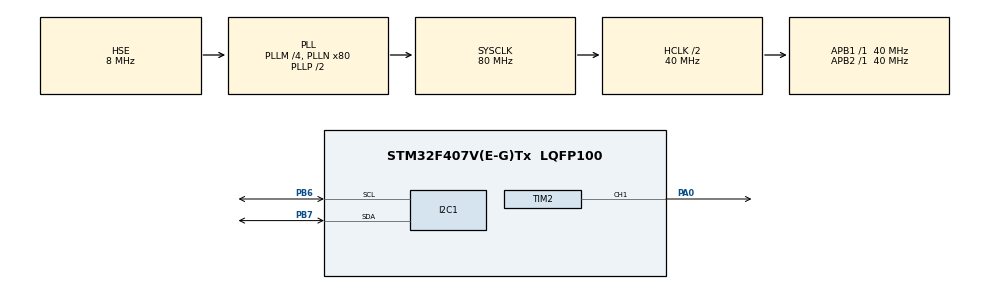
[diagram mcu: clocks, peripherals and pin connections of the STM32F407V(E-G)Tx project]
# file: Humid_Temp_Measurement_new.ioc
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Dma.Request0=TIM2_CH1
Dma.TIM2_CH1.0.Direction=DMA_MEMORY_TO_PERIPH
Dma.TIM2_CH1.0.FIFOMode=DMA_FIFOMODE_DISABLE
Dma.TIM2_CH1.0.Instance=DMA1_Stream5
Dma.TIM2_CH1.0.MemDataAlignment=DMA_MDATAALIGN_HALFWORD
Dma.TIM2_CH1.0.MemInc=DMA_MINC_ENABLE
Dma.TIM2_CH1.0.Mode=DMA_NORMAL
Dma.TIM2_CH1.0.PeriphDataAlignment=DMA_PDATAALIGN_HALFWORD
Dma.TIM2_CH1.0.PeriphInc=DMA_PINC_DISABLE
Dma.TIM2_CH1.0.Priority=DMA_PRIORITY_LOW
Mcu.Family=STM32F4
Mcu.Name=STM32F407V(E-G)Tx
Mcu.Package=LQFP100
NVIC.DMA1_Stream5_IRQn=true\:0\:0\:false\:false\:true\:false\:true\:true
NVIC.PriorityGroup=NVIC_PRIORITYGROUP_4
NVIC.TIM3_IRQn=true\:0\:0\:false\:false\:true\:true\:true\:true
PA0-WKUP.Signal=S_TIM2_CH1_ETR
PA13.Mode=Serial_Wire
PA13.Signal=SYS_JTMS-SWDIO
PA14.Mode=Serial_Wire
PA14.Signal=SYS_JTCK-SWCLK
PB6.Mode=I2C
PB6.Signal=I2C1_SCL
PB7.Mode=I2C
PB7.Signal=I2C1_SDA
PH0-OSC_IN.Mode=HSE-External-Oscillator
PH0-OSC_IN.Signal=RCC_OSC_IN
PH1-OSC_OUT.Mode=HSE-External-Oscillator
PH1-OSC_OUT.Signal=RCC_OSC_OUT
ProjectManager.HeapSize=0x200
ProjectManager.StackSize=0x400
ProjectManager.TargetToolchain=STM32CubeIDE
RCC.48MHZClocksFreq_Value=40000000
RCC.AHBCLKDivider=RCC_SYSCLK_DIV2
RCC.AHBFreq_Value=40000000
RCC.APB1Freq_Value=40000000
RCC.APB1TimFreq_Value=40000000
RCC.APB2Freq_Value=40000000
RCC.APB2TimFreq_Value=40000000
RCC.CortexFreq_Value=40000000
RCC.HCLKFreq_Value=40000000
RCC.HSE_VALUE=8000000
RCC.HSI_VALUE=16000000
RCC.LSE_VALUE=32768
RCC.PLLM=4
RCC.PLLN=80
RCC.PLLSourceVirtual=RCC_PLLSOURCE_HSE
RCC.SYSCLKFreq_VALUE=80000000
RCC.SYSCLKSource=RCC_SYSCLKSOURCE_PLLCLK
RCC.VCOOutputFreq_Value=160000000
SH.S_TIM2_CH1_ETR.0=TIM2_CH1,PWM Generation1 CH1
TIM2.Channel-PWM\ Generation1\ CH1=TIM_CHANNEL_1
TIM2.Period=2000
TIM2.Prescaler=40-1
TIM3.Period=0xffff-1
TIM3.Prescaler=40-1
VP_TIM2_VS_ClockSourceINT.Mode=Internal
VP_TIM3_VS_ClockSourceINT.Mode=Internal
board=custom

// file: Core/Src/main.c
/* USER CODE BEGIN Header */
/**
  ******************************************************************************
  * @file           : main.c
  * @brief          : Main program body
  ******************************************************************************
  * @attention
  *
  * Copyright (c) 2024 STMicroelectronics.
  * All rights reserved.
  *
  * This software is licensed under terms that can be found in the LICENSE file
  * in the root directory of this software component.
  * If no LICENSE file comes with this software, it is provided AS-IS.
  *
  ******************************************************************************
  */
/* USER CODE END Header */
#include "main.h"

/* USER CODE BEGIN Includes */
#include "i2c-lcd.h"
#include "stdio.h"
#include "DHT11.h"
/* USER CODE END Includes */

I2C_HandleTypeDef hi2c1;

TIM_HandleTypeDef htim2;
TIM_HandleTypeDef htim3;
DMA_HandleTypeDef hdma_tim2_ch1;

void SystemClock_Config(void);
static void MX_GPIO_Init(void);
static void MX_DMA_Init(void);
static void MX_I2C1_Init(void);
static void MX_TIM2_Init(void);
static void MX_TIM3_Init(void);

/* USER CODE BEGIN PFP */
/********************************DHT11**********************************/
void display_Temp(float Temp);
void display_Humid(float RH);

/********************************DS3231**********************************/
#define DS3231_ADDRESS 0xD0

uint8_t dec_To_Bcd(int val);
int bcd_To_Dec(uint8_t val);

void set_Time(uint8_t sec, uint8_t min, uint8_t hour, uint8_t dow, uint8_t dom,
			  uint8_t month, uint8_t year);
void get_Time(void);

typedef struct {
	uint8_t second;
	uint8_t minute;
	uint8_t hour;
	uint8_t dayOfWeek;
	uint8_t dayOfMonth;
	uint8_t month;
	uint8_t year;
} TIME;
/* USER CODE END PFP */

/* USER CODE BEGIN 0 */
/********************************DHT11**********************************/
uint8_t RHI, RHD, TCI, TCD, SUM;
float tCelsius = 0;
float tFahrenheit = 0;
float RH = 0;

void display_Temp(float Temp) {
	char str[10];
	lcd_put_cur(0, 0);
	sprintf(str, "T:%.1f*C", Temp);
	lcd_send_string(str);
}

void display_Humid(float RH) {
	char str[10];
	lcd_put_cur(0, 9);
	sprintf(str, "H:%.1f", RH);
	lcd_send_string(str);
}

/********************************DS3231**********************************/
TIME time;

uint8_t dec_To_Bcd(int val) {
	return (uint8_t)((val/10*16) + (val%10));
}

int bcd_To_Dec(uint8_t val) {
	return (int)((val/16*10) + (val%16));
}

void set_Time(uint8_t sec, uint8_t min, uint8_t hour, uint8_t dow, uint8_t dom,
			  uint8_t month, uint8_t year) {
	uint8_t set_time_buffer[7];
	set_time_buffer[0] = dec_To_Bcd(sec);
	set_time_buffer[1] = dec_To_Bcd(min);
	set_time_buffer[2] = dec_To_Bcd(hour);
	set_time_buffer[3] = dec_To_Bcd(dow);
	set_time_buffer[4] = dec_To_Bcd(dom);
	set_time_buffer[5] = dec_To_Bcd(month);
	set_time_buffer[6] = dec_To_Bcd(year);

	HAL_I2C_Mem_Write(&hi2c1, DS3231_ADDRESS, 0x00, 1, set_time_buffer, 7, 1000);
}

void get_Time(void) {
	uint8_t get_time_buffer[7];
	HAL_I2C_Mem_Read(&hi2c1, DS3231_ADDRESS, 0x00, 1, get_time_buffer, 7, 1000);

	time.second 	= bcd_To_Dec(get_time_buffer[0]);
	time.minute 	= bcd_To_Dec(get_time_buffer[1]);
	time.hour 		= bcd_To_Dec(get_time_buffer[2]);
	time.dayOfWeek 	= bcd_To_Dec(get_time_buffer[3]);
	time.dayOfMonth = bcd_To_Dec(get_time_buffer[4]);
	time.month 		= bcd_To_Dec(get_time_buffer[5]);
	time.year 		= bcd_To_Dec(get_time_buffer[6]);
}

/* USER CODE END 0 */

int main(void)
{

  /* MCU Configuration--------------------------------------------------------*/

  /* Reset of all peripherals, Initializes the Flash interface and the Systick. */
  HAL_Init();

  /* Configure the system clock */
  SystemClock_Config();

  /* Initialize all configured peripherals */
  MX_GPIO_Init();
  MX_DMA_Init();
  MX_I2C1_Init();
  MX_TIM2_Init();
  MX_TIM3_Init();
  /* USER CODE BEGIN 2 */
  HAL_TIM_Base_Start(&htim3);
  HAL_TIM_Base_Start_IT(&htim3);

  HAL_TIM_PWM_Start(&htim2, TIM_CHANNEL_1);
  /* USER CODE END 2 */

  /* Infinite loop */
  /* USER CODE BEGIN WHILE */

  lcd_init();
  lcd_put_cur(0, 0);

  lcd_send_string("Hello world!");

  HAL_Delay(4000);
  lcd_clear();

//  set_Time(30, 12, 21, 6, 12, 4, 24);
  char time_buffer[30];

  while (1)
  {
	  display_Temp(tCelsius);
	  display_Humid(RH);

	  if(DHT11_Start()) {
		  RHI = DHT11_Read(); // Relative humidity integral
		  RHD = DHT11_Read(); // Relative humidity decimal
		  TCI = DHT11_Read(); // Celsius integral
		  TCD = DHT11_Read(); // Celsius decimal
		  SUM = DHT11_Read(); // Check sum

		  if(SUM == RHI + RHD + TCI + TCD) {
			  // Can use RHI and TCI for any purposes if whole number only needed
			  tCelsius = (float)TCI + (float)(TCD/10.0);
			  tFahrenheit = tCelsius * 9/5 + 32;
			  RH = (float)RHI + (float)(RHD/10.0);
			  // Can use tCelsius, tFahrenheit and RH for any purposes
		  }
	  }

	  get_Time();
	  sprintf(time_buffer, "%02d:%02d", time.hour, time.minute);
	  lcd_put_cur(1, 0);
	  lcd_send_string(time_buffer);

	  sprintf(time_buffer, "%02d-%02d-20%02d", time.dayOfMonth, time.month, time.year);
	  lcd_put_cur(1, 6);
	  lcd_send_string(time_buffer);

	  HAL_Delay(1000);
    /* USER CODE END WHILE */

  }
}

void SystemClock_Config(void)
{
  RCC_OscInitTypeDef RCC_OscInitStruct = {0};
  RCC_ClkInitTypeDef RCC_ClkInitStruct = {0};

  /** Configure the main internal regulator output voltage
  */
  __HAL_RCC_PWR_CLK_ENABLE();
  __HAL_PWR_VOLTAGESCALING_CONFIG(PWR_REGULATOR_VOLTAGE_SCALE1);

  /** Initializes the RCC Oscillators according to the specified parameters
  * in the RCC_OscInitTypeDef structure.
  */
  RCC_OscInitStruct.OscillatorType = RCC_OSCILLATORTYPE_HSE;
  RCC_OscInitStruct.HSEState = RCC_HSE_ON;
  RCC_OscInitStruct.PLL.PLLState = RCC_PLL_ON;
  RCC_OscInitStruct.PLL.PLLSource = RCC_PLLSOURCE_HSE;
  RCC_OscInitStruct.PLL.PLLM = 4;
  RCC_OscInitStruct.PLL.PLLN = 80;
  RCC_OscInitStruct.PLL.PLLP = RCC_PLLP_DIV2;
  RCC_OscInitStruct.PLL.PLLQ = 4;
  if (HAL_RCC_OscConfig(&RCC_OscInitStruct) != HAL_OK)
  {
    Error_Handler();
  }

  /** Initializes the CPU, AHB and APB buses clocks
  */
  RCC_ClkInitStruct.ClockType = RCC_CLOCKTYPE_HCLK|RCC_CLOCKTYPE_SYSCLK
                              |RCC_CLOCKTYPE_PCLK1|RCC_CLOCKTYPE_PCLK2;
  RCC_ClkInitStruct.SYSCLKSource = RCC_SYSCLKSOURCE_PLLCLK;
  RCC_ClkInitStruct.AHBCLKDivider = RCC_SYSCLK_DIV2;
  RCC_ClkInitStruct.APB1CLKDivider = RCC_HCLK_DIV1;
  RCC_ClkInitStruct.APB2CLKDivider = RCC_HCLK_DIV1;

  if (HAL_RCC_ClockConfig(&RCC_ClkInitStruct, FLASH_LATENCY_1) != HAL_OK)
  {
    Error_Handler();
  }
}

static void MX_I2C1_Init(void)
{

  hi2c1.Instance = I2C1;
  hi2c1.Init.ClockSpeed = 100000;
  hi2c1.Init.DutyCycle = I2C_DUTYCYCLE_2;
  hi2c1.Init.OwnAddress1 = 0;
  hi2c1.Init.AddressingMode = I2C_ADDRESSINGMODE_7BIT;
  hi2c1.Init.DualAddressMode = I2C_DUALADDRESS_DISABLE;
  hi2c1.Init.OwnAddress2 = 0;
  hi2c1.Init.GeneralCallMode = I2C_GENERALCALL_DISABLE;
  hi2c1.Init.NoStretchMode = I2C_NOSTRETCH_DISABLE;
  if (HAL_I2C_Init(&hi2c1) != HAL_OK)
  {
    Error_Handler();
  }

}

static void MX_TIM2_Init(void)
{

  TIM_ClockConfigTypeDef sClockSourceConfig = {0};
  TIM_MasterConfigTypeDef sMasterConfig = {0};
  TIM_OC_InitTypeDef sConfigOC = {0};

  htim2.Instance = TIM2;
  htim2.Init.Prescaler = 40-1;
  htim2.Init.CounterMode = TIM_COUNTERMODE_UP;
  htim2.Init.Period = 2000;
  htim2.Init.ClockDivision = TIM_CLOCKDIVISION_DIV1;
  htim2.Init.AutoReloadPreload = TIM_AUTORELOAD_PRELOAD_DISABLE;
  if (HAL_TIM_Base_Init(&htim2) != HAL_OK)
  {
    Error_Handler();
  }
  sClockSourceConfig.ClockSource = TIM_CLOCKSOURCE_INTERNAL;
  if (HAL_TIM_ConfigClockSource(&htim2, &sClockSourceConfig) != HAL_OK)
  {
    Error_Handler();
  }
  if (HAL_TIM_PWM_Init(&htim2) != HAL_OK)
  {
    Error_Handler();
  }
  sMasterConfig.MasterOutputTrigger = TIM_TRGO_RESET;
  sMasterConfig.MasterSlaveMode = TIM_MASTERSLAVEMODE_DISABLE;
  if (HAL_TIMEx_MasterConfigSynchronization(&htim2, &sMasterConfig) != HAL_OK)
  {
    Error_Handler();
  }
  sConfigOC.OCMode = TIM_OCMODE_PWM1;
  sConfigOC.Pulse = 0;
  sConfigOC.OCPolarity = TIM_OCPOLARITY_HIGH;
  sConfigOC.OCFastMode = TIM_OCFAST_DISABLE;
  if (HAL_TIM_PWM_ConfigChannel(&htim2, &sConfigOC, TIM_CHANNEL_1) != HAL_OK)
  {
    Error_Handler();
  }
  HAL_TIM_MspPostInit(&htim2);

}

static void MX_TIM3_Init(void)
{

  TIM_ClockConfigTypeDef sClockSourceConfig = {0};
  TIM_MasterConfigTypeDef sMasterConfig = {0};

  htim3.Instance = TIM3;
  htim3.Init.Prescaler = 40-1;
  htim3.Init.CounterMode = TIM_COUNTERMODE_UP;
  htim3.Init.Period = 0xffff-1;
  htim3.Init.ClockDivision = TIM_CLOCKDIVISION_DIV1;
  htim3.Init.AutoReloadPreload = TIM_AUTORELOAD_PRELOAD_DISABLE;
  if (HAL_TIM_Base_Init(&htim3) != HAL_OK)
  {
    Error_Handler();
  }
  sClockSourceConfig.ClockSource = TIM_CLOCKSOURCE_INTERNAL;
  if (HAL_TIM_ConfigClockSource(&htim3, &sClockSourceConfig) != HAL_OK)
  {
    Error_Handler();
  }
  sMasterConfig.MasterOutputTrigger = TIM_TRGO_RESET;
  sMasterConfig.MasterSlaveMode = TIM_MASTERSLAVEMODE_DISABLE;
  if (HAL_TIMEx_MasterConfigSynchronization(&htim3, &sMasterConfig) != HAL_OK)
  {
    Error_Handler();
  }

}

static void MX_DMA_Init(void)
{

  /* DMA controller clock enable */
  __HAL_RCC_DMA1_CLK_ENABLE();

  /* DMA interrupt init */
  /* DMA1_Stream5_IRQn interrupt configuration */
  HAL_NVIC_SetPriority(DMA1_Stream5_IRQn, 0, 0);
  HAL_NVIC_EnableIRQ(DMA1_Stream5_IRQn);

}

static void MX_GPIO_Init(void)
{

  /* GPIO Ports Clock Enable */
  __HAL_RCC_GPIOH_CLK_ENABLE();
  __HAL_RCC_GPIOA_CLK_ENABLE();
  __HAL_RCC_GPIOB_CLK_ENABLE();

}

void Error_Handler(void)
{
  __disable_irq();
  while (1)
  {
  }
}
